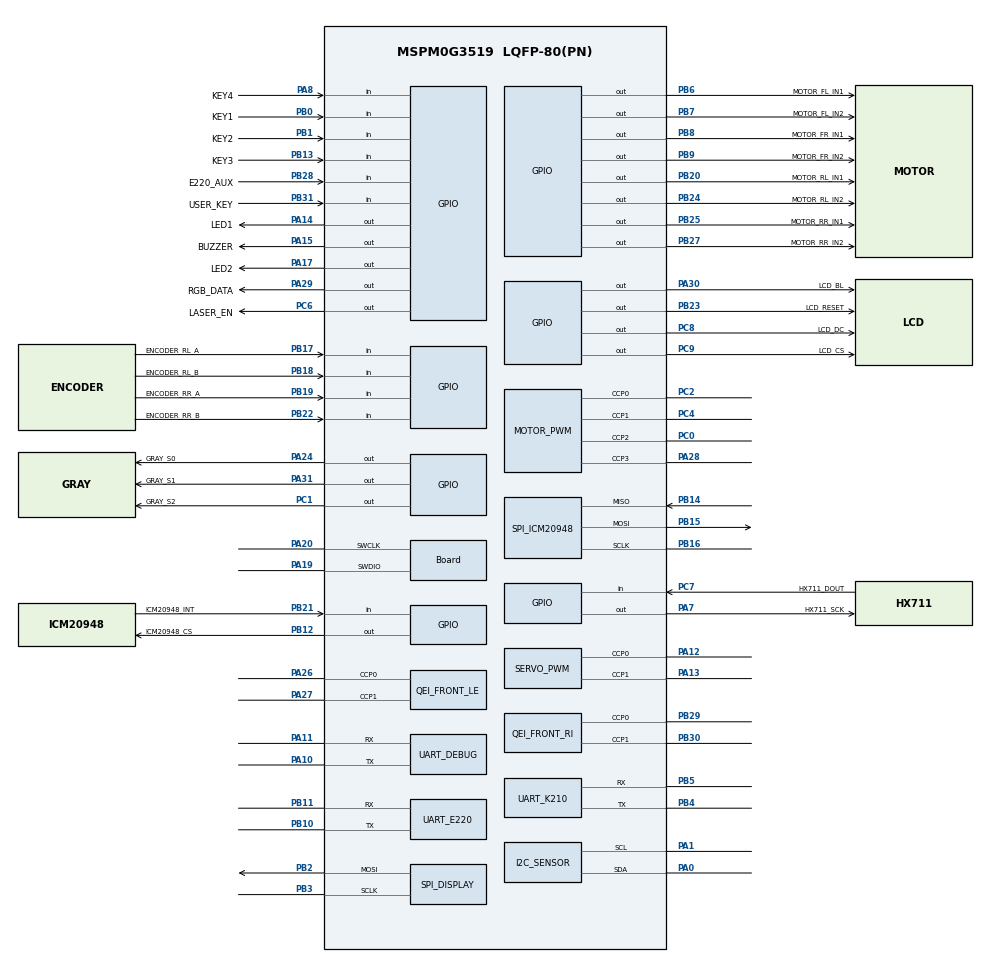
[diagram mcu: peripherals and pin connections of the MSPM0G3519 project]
//@cliArgs --device "MSPM0G351X" --package "LQFP-80(PN)" --part "Default"
//@v2CliArgs --device "MSPM0G3519" --package "LQFP-80(PN)"

/**
 * Import the modules used in this configuration.
 */
const Board         = scripting.addModule("/ti/driverlib/Board", {}, false);
const GPIO          = scripting.addModule("/ti/driverlib/GPIO", {}, false);
const GPIOA_BOARD   = GPIO.addInstance();
const GPIOB_BOARD   = GPIO.addInstance();
const GPIOC_BOARD   = GPIO.addInstance();
const PWM           = scripting.addModule("/ti/driverlib/PWM", {}, false);
const MOTOR_PWM     = PWM.addInstance();
const SERVO_PWM     = PWM.addInstance();
const QEI           = scripting.addModule("/ti/driverlib/QEI", {}, false);
const QEI_FRONT_LEFT  = QEI.addInstance();
const QEI_FRONT_RIGHT = QEI.addInstance();
const UART          = scripting.addModule("/ti/driverlib/UART", {}, false);
const UART_K210     = UART.addInstance();
const UART_E220     = UART.addInstance();
const UART_DEBUG    = UART.addInstance();
const I2C           = scripting.addModule("/ti/driverlib/I2C", {}, false);
const I2C_SENSOR    = I2C.addInstance();
const SPI           = scripting.addModule("/ti/driverlib/SPI", {}, false);
const SPI_DISPLAY   = SPI.addInstance();
const SPI_ICM20948  = SPI.addInstance();
const ADC12         = scripting.addModule("/ti/driverlib/ADC12", {}, false);
const ADC_GRAY      = ADC12.addInstance();
const SYSCTL        = scripting.addModule("/ti/driverlib/SYSCTL");
const SYSTICK       = scripting.addModule("/ti/driverlib/SYSTICK");
const ProjectConfig = scripting.addModule("/ti/project_config/ProjectConfig");

/**
 * Write custom configuration values to the imported modules.
 */

Board.peripheral.$assign          = "DEBUGSS";
Board.peripheral.swclkPin.$assign = "PA20";
Board.peripheral.swdioPin.$assign = "PA19";

GPIOA_BOARD.$name = "GPIO_BOARD_OUTPUTS";
GPIOA_BOARD.port  = "PORTA";
GPIOA_BOARD.associatedPins.create(9);

GPIOA_BOARD.associatedPins[0].$name        = "LED1";
GPIOA_BOARD.associatedPins[0].assignedPin  = "14";
GPIOA_BOARD.associatedPins[0].initialValue = "SET";
GPIOA_BOARD.associatedPins[0].pin.$assign  = "PA14";

GPIOA_BOARD.associatedPins[1].$name        = "LED2";
GPIOA_BOARD.associatedPins[1].assignedPin  = "17";
GPIOA_BOARD.associatedPins[1].initialValue = "SET";
GPIOA_BOARD.associatedPins[1].pin.$assign  = "PA17";

GPIOA_BOARD.associatedPins[2].$name        = "RGB_DATA";
GPIOA_BOARD.associatedPins[2].assignedPin  = "29";
GPIOA_BOARD.associatedPins[2].initialValue = "CLEARED";
GPIOA_BOARD.associatedPins[2].pin.$assign  = "PA29";

GPIOA_BOARD.associatedPins[3].$name        = "LCD_BL";
GPIOA_BOARD.associatedPins[3].assignedPin  = "30";
GPIOA_BOARD.associatedPins[3].initialValue = "CLEARED";
GPIOA_BOARD.associatedPins[3].pin.$assign  = "PA30";

GPIOA_BOARD.associatedPins[4].$name        = "GRAY_S0";
GPIOA_BOARD.associatedPins[4].assignedPin  = "24";
GPIOA_BOARD.associatedPins[4].initialValue = "CLEARED";
GPIOA_BOARD.associatedPins[4].pin.$assign  = "PA24";

GPIOA_BOARD.associatedPins[5].$name        = "GRAY_S1";
GPIOA_BOARD.associatedPins[5].assignedPin  = "31";
GPIOA_BOARD.associatedPins[5].initialValue = "CLEARED";
GPIOA_BOARD.associatedPins[5].pin.$assign  = "PA31";

GPIOA_BOARD.associatedPins[6].$name        = "HX711_SCK";
GPIOA_BOARD.associatedPins[6].assignedPin  = "7";
GPIOA_BOARD.associatedPins[6].initialValue = "CLEARED";
GPIOA_BOARD.associatedPins[6].pin.$assign  = "PA7";

GPIOA_BOARD.associatedPins[7].$name        = "BUZZER";
GPIOA_BOARD.associatedPins[7].assignedPin  = "15";
GPIOA_BOARD.associatedPins[7].initialValue = "SET";
GPIOA_BOARD.associatedPins[7].pin.$assign  = "PA15";
GPIOA_BOARD.associatedPins[8].$name            = "KEY4";
GPIOA_BOARD.associatedPins[8].assignedPin      = "8";
GPIOA_BOARD.associatedPins[8].direction        = "INPUT";
GPIOA_BOARD.associatedPins[8].internalResistor = "PULL_UP";
GPIOA_BOARD.associatedPins[8].pin.$assign      = "PA8";

GPIOB_BOARD.$name = "GPIO_BOARD_IO";
GPIOB_BOARD.port  = "PORTB";
GPIOB_BOARD.associatedPins.create(20);

GPIOB_BOARD.associatedPins[0].$name        = "ICM20948_CS";
GPIOB_BOARD.associatedPins[0].assignedPin  = "12";
GPIOB_BOARD.associatedPins[0].initialValue = "SET";
GPIOB_BOARD.associatedPins[0].pin.$assign  = "PB12";

GPIOB_BOARD.associatedPins[1].$name       = "ICM20948_INT";
GPIOB_BOARD.associatedPins[1].assignedPin = "21";
GPIOB_BOARD.associatedPins[1].direction   = "INPUT";
GPIOB_BOARD.associatedPins[1].interruptEn = true;
GPIOB_BOARD.associatedPins[1].polarity    = "RISE_FALL";
GPIOB_BOARD.associatedPins[1].pin.$assign = "PB21";

GPIOB_BOARD.associatedPins[2].$name            = "USER_KEY";
GPIOB_BOARD.associatedPins[2].assignedPin      = "31";
GPIOB_BOARD.associatedPins[2].direction        = "INPUT";
GPIOB_BOARD.associatedPins[2].internalResistor = "PULL_UP";
GPIOB_BOARD.associatedPins[2].pin.$assign      = "PB31";

GPIOB_BOARD.associatedPins[3].$name        = "MOTOR_FL_IN1";
GPIOB_BOARD.associatedPins[3].assignedPin  = "6";
GPIOB_BOARD.associatedPins[3].initialValue = "CLEARED";
GPIOB_BOARD.associatedPins[3].pin.$assign  = "PB6";

GPIOB_BOARD.associatedPins[4].$name        = "MOTOR_FL_IN2";
GPIOB_BOARD.associatedPins[4].assignedPin  = "7";
GPIOB_BOARD.associatedPins[4].initialValue = "CLEARED";
GPIOB_BOARD.associatedPins[4].pin.$assign  = "PB7";

GPIOB_BOARD.associatedPins[5].$name        = "MOTOR_FR_IN1";
GPIOB_BOARD.associatedPins[5].assignedPin  = "8";
GPIOB_BOARD.associatedPins[5].initialValue = "CLEARED";
GPIOB_BOARD.associatedPins[5].pin.$assign  = "PB8";

GPIOB_BOARD.associatedPins[6].$name        = "MOTOR_FR_IN2";
GPIOB_BOARD.associatedPins[6].assignedPin  = "9";
GPIOB_BOARD.associatedPins[6].initialValue = "CLEARED";
GPIOB_BOARD.associatedPins[6].pin.$assign  = "PB9";

GPIOB_BOARD.associatedPins[7].$name        = "MOTOR_RL_IN1";
GPIOB_BOARD.associatedPins[7].assignedPin  = "20";
GPIOB_BOARD.associatedPins[7].initialValue = "CLEARED";
GPIOB_BOARD.associatedPins[7].pin.$assign  = "PB20";

GPIOB_BOARD.associatedPins[8].$name        = "MOTOR_RL_IN2";
GPIOB_BOARD.associatedPins[8].assignedPin  = "24";
GPIOB_BOARD.associatedPins[8].initialValue = "CLEARED";
GPIOB_BOARD.associatedPins[8].pin.$assign  = "PB24";

GPIOB_BOARD.associatedPins[9].$name        = "MOTOR_RR_IN1";
GPIOB_BOARD.associatedPins[9].assignedPin  = "25";
GPIOB_BOARD.associatedPins[9].initialValue = "CLEARED";
GPIOB_BOARD.associatedPins[9].pin.$assign  = "PB25";

GPIOB_BOARD.associatedPins[10].$name        = "MOTOR_RR_IN2";
GPIOB_BOARD.associatedPins[10].assignedPin  = "27";
GPIOB_BOARD.associatedPins[10].initialValue = "CLEARED";
GPIOB_BOARD.associatedPins[10].pin.$assign  = "PB27";

GPIOB_BOARD.associatedPins[11].$name            = "ENCODER_RL_A";
GPIOB_BOARD.associatedPins[11].assignedPin      = "17";
GPIOB_BOARD.associatedPins[11].direction        = "INPUT";
GPIOB_BOARD.associatedPins[11].internalResistor = "PULL_UP";
GPIOB_BOARD.associatedPins[11].inputFilter      = "3_CYCLES";
GPIOB_BOARD.associatedPins[11].interruptEn      = true;
GPIOB_BOARD.associatedPins[11].polarity         = "RISE_FALL";
GPIOB_BOARD.associatedPins[11].pin.$assign      = "PB17";

GPIOB_BOARD.associatedPins[12].$name            = "ENCODER_RL_B";
GPIOB_BOARD.associatedPins[12].assignedPin      = "18";
GPIOB_BOARD.associatedPins[12].direction        = "INPUT";
GPIOB_BOARD.associatedPins[12].internalResistor = "PULL_UP";
GPIOB_BOARD.associatedPins[12].inputFilter      = "3_CYCLES";
GPIOB_BOARD.associatedPins[12].interruptEn      = true;
GPIOB_BOARD.associatedPins[12].polarity         = "RISE_FALL";
GPIOB_BOARD.associatedPins[12].pin.$assign      = "PB18";

GPIOB_BOARD.associatedPins[13].$name            = "ENCODER_RR_A";
GPIOB_BOARD.associatedPins[13].assignedPin      = "19";
GPIOB_BOARD.associatedPins[13].direction        = "INPUT";
GPIOB_BOARD.associatedPins[13].internalResistor = "PULL_UP";
GPIOB_BOARD.associatedPins[13].inputFilter      = "3_CYCLES";
GPIOB_BOARD.associatedPins[13].interruptEn      = true;
GPIOB_BOARD.associatedPins[13].polarity         = "RISE_FALL";
GPIOB_BOARD.associatedPins[13].pin.$assign      = "PB19";

GPIOB_BOARD.associatedPins[14].$name            = "ENCODER_RR_B";
GPIOB_BOARD.associatedPins[14].assignedPin      = "22";
GPIOB_BOARD.associatedPins[14].direction        = "INPUT";
GPIOB_BOARD.associatedPins[14].internalResistor = "PULL_UP";
GPIOB_BOARD.associatedPins[14].inputFilter      = "3_CYCLES";
GPIOB_BOARD.associatedPins[14].interruptEn      = true;
GPIOB_BOARD.associatedPins[14].polarity         = "RISE_FALL";
GPIOB_BOARD.associatedPins[14].pin.$assign      = "PB22";

GPIOB_BOARD.associatedPins[15].$name        = "LCD_RESET";
GPIOB_BOARD.associatedPins[15].assignedPin  = "23";
GPIOB_BOARD.associatedPins[15].initialValue = "SET";
GPIOB_BOARD.associatedPins[15].pin.$assign  = "PB23";

GPIOB_BOARD.associatedPins[16].$name            = "E220_AUX";
GPIOB_BOARD.associatedPins[16].assignedPin      = "28";
GPIOB_BOARD.associatedPins[16].direction        = "INPUT";
GPIOB_BOARD.associatedPins[16].internalResistor = "PULL_UP";
GPIOB_BOARD.associatedPins[16].pin.$assign      = "PB28";
GPIOB_BOARD.associatedPins[17].$name            = "KEY1";
GPIOB_BOARD.associatedPins[17].assignedPin      = "0";
GPIOB_BOARD.associatedPins[17].direction        = "INPUT";
GPIOB_BOARD.associatedPins[17].internalResistor = "PULL_UP";
GPIOB_BOARD.associatedPins[17].pin.$assign      = "PB0";

GPIOB_BOARD.associatedPins[18].$name            = "KEY2";
GPIOB_BOARD.associatedPins[18].assignedPin      = "1";
GPIOB_BOARD.associatedPins[18].direction        = "INPUT";
GPIOB_BOARD.associatedPins[18].internalResistor = "PULL_UP";
GPIOB_BOARD.associatedPins[18].pin.$assign      = "PB1";

GPIOB_BOARD.associatedPins[19].$name            = "KEY3";
GPIOB_BOARD.associatedPins[19].assignedPin      = "13";
GPIOB_BOARD.associatedPins[19].direction        = "INPUT";
GPIOB_BOARD.associatedPins[19].internalResistor = "PULL_UP";
GPIOB_BOARD.associatedPins[19].pin.$assign      = "PB13";

GPIOC_BOARD.$name = "GPIO_DISPLAY_GRAY";
GPIOC_BOARD.port  = "PORTC";
GPIOC_BOARD.associatedPins.create(5);

GPIOC_BOARD.associatedPins[0].$name        = "LCD_DC";
GPIOC_BOARD.associatedPins[0].assignedPin  = "8";
GPIOC_BOARD.associatedPins[0].initialValue = "CLEARED";
GPIOC_BOARD.associatedPins[0].pin.$assign  = "PC8";

GPIOC_BOARD.associatedPins[1].$name        = "LCD_CS";
GPIOC_BOARD.associatedPins[1].assignedPin  = "9";
GPIOC_BOARD.associatedPins[1].initialValue = "SET";
GPIOC_BOARD.associatedPins[1].pin.$assign  = "PC9";

GPIOC_BOARD.associatedPins[2].$name        = "GRAY_S2";
GPIOC_BOARD.associatedPins[2].assignedPin  = "1";
GPIOC_BOARD.associatedPins[2].initialValue = "CLEARED";
GPIOC_BOARD.associatedPins[2].pin.$assign  = "PC1";

GPIOC_BOARD.associatedPins[3].$name        = "LASER_EN";
GPIOC_BOARD.associatedPins[3].assignedPin  = "6";
GPIOC_BOARD.associatedPins[3].initialValue = "CLEARED";
GPIOC_BOARD.associatedPins[3].pin.$assign  = "PC6";

GPIOC_BOARD.associatedPins[4].$name            = "HX711_DOUT";
GPIOC_BOARD.associatedPins[4].assignedPin      = "7";
GPIOC_BOARD.associatedPins[4].direction        = "INPUT";
GPIOC_BOARD.associatedPins[4].internalResistor = "PULL_UP";
GPIOC_BOARD.associatedPins[4].pin.$assign      = "PC7";

/*
 * 四路直流电机 PWM 共用 TIMA0，32 MHz / 1600 = 20 kHz。
 * 所有通道初始占空比为 0，避免上电时电机误动作。
 */
MOTOR_PWM.$name                      = "PWM_MOTOR";
MOTOR_PWM.pwmMode                    = "EDGE_ALIGN_UP";
MOTOR_PWM.timerCount                 = 1600;
MOTOR_PWM.timerStartTimer            = true;
MOTOR_PWM.ccIndex                    = [0,1,2,3];
MOTOR_PWM.peripheral.$assign         = "TIMA0";
MOTOR_PWM.peripheral.ccp0Pin.$assign = "PC2";
MOTOR_PWM.peripheral.ccp1Pin.$assign = "PC4";
MOTOR_PWM.peripheral.ccp2Pin.$assign = "PC0";
MOTOR_PWM.peripheral.ccp3Pin.$assign = "PA28";
MOTOR_PWM.PWM_CHANNEL_0.$name        = "MOTOR_PWM_FL";
MOTOR_PWM.PWM_CHANNEL_0.ccValue      = 1600;
MOTOR_PWM.PWM_CHANNEL_1.$name        = "MOTOR_PWM_FR";
MOTOR_PWM.PWM_CHANNEL_1.ccValue      = 1600;
MOTOR_PWM.PWM_CHANNEL_2.$name        = "MOTOR_PWM_RL";
MOTOR_PWM.PWM_CHANNEL_2.ccValue      = 1600;
MOTOR_PWM.PWM_CHANNEL_3.$name        = "MOTOR_PWM_RR";
MOTOR_PWM.PWM_CHANNEL_3.ccValue      = 1600;

/*
 * TIMG0 以 1 MHz 计数、20 ms 周期驱动两路舵机。
 * 初始 compare=LOAD 表示 0% 有效脉冲，避免上电瞬间舵机误动作。
 */
SERVO_PWM.$name                      = "PWM_SERVO";
SERVO_PWM.pwmMode                    = "EDGE_ALIGN_UP";
SERVO_PWM.clockPrescale              = 32;
SERVO_PWM.timerCount                 = 20000;
SERVO_PWM.timerStartTimer            = true;
SERVO_PWM.ccIndex                    = [0,1];
SERVO_PWM.peripheral.$assign         = "TIMG0";
SERVO_PWM.peripheral.ccp0Pin.$assign = "PA12";
SERVO_PWM.peripheral.ccp1Pin.$assign = "PA13";
SERVO_PWM.PWM_CHANNEL_0.$name        = "SERVO_HORIZONTAL";
SERVO_PWM.PWM_CHANNEL_0.ccValue      = 20000;
SERVO_PWM.PWM_CHANNEL_1.$name        = "SERVO_PITCH";
SERVO_PWM.PWM_CHANNEL_1.ccValue      = 20000;

/*
 * MSPM0G3519 只有 TIMG8/TIMG9 两组硬件 QEI。
 * 先将它们固定给左右前轮；4WD 后轮后续使用 GPIO 双边沿软件解码。
 */
QEI_FRONT_LEFT.$name                      = "QEI_FRONT_LEFT";
QEI_FRONT_LEFT.timerStartTimer            = true;
QEI_FRONT_LEFT.peripheral.$assign         = "TIMG8";
QEI_FRONT_LEFT.peripheral.ccp0Pin.$assign = "PA26";
QEI_FRONT_LEFT.peripheral.ccp1Pin.$assign = "PA27";

QEI_FRONT_RIGHT.$name                      = "QEI_FRONT_RIGHT";
QEI_FRONT_RIGHT.timerStartTimer            = true;
QEI_FRONT_RIGHT.peripheral.$assign         = "TIMG9";
QEI_FRONT_RIGHT.peripheral.ccp0Pin.$assign = "PB29";
QEI_FRONT_RIGHT.peripheral.ccp1Pin.$assign = "PB30";

/*
 * 三路 UART 独立分工，均为 115200-8-N-1：
 * UART0：板载 CH340 / Type-C 调试串口，PA10 TX、PA11 RX；
 * UART1：K210，PB4 TX、PB5 RX；
 * UART4：E220，PB10 TX、PB11 RX。
 */
UART_DEBUG.$name                    = "UART_DEBUG";
UART_DEBUG.targetBaudRate           = 115200;
UART_DEBUG.enableFIFO               = true;
UART_DEBUG.rxFifoThreshold          = "DL_UART_RX_FIFO_LEVEL_ONE_ENTRY";
UART_DEBUG.txFifoThreshold          = "DL_UART_TX_FIFO_LEVEL_3_4_EMPTY";
UART_DEBUG.enabledInterrupts        = ["RX","TX"];
UART_DEBUG.peripheral.$assign       = "UART0";
UART_DEBUG.peripheral.txPin.$assign = "PA10";
UART_DEBUG.peripheral.rxPin.$assign = "PA11";

UART_K210.$name                    = "UART_K210";
UART_K210.targetBaudRate           = 115200;
UART_K210.enableFIFO               = true;
UART_K210.rxFifoThreshold          = "DL_UART_RX_FIFO_LEVEL_ONE_ENTRY";
UART_K210.txFifoThreshold          = "DL_UART_TX_FIFO_LEVEL_3_4_EMPTY";
UART_K210.enabledInterrupts        = ["RX","TX"];
UART_K210.peripheral.$assign       = "UART1";
UART_K210.peripheral.txPin.$assign = "PB4";
UART_K210.peripheral.rxPin.$assign = "PB5";

UART_E220.$name                    = "UART_E220";
UART_E220.targetBaudRate           = 115200;
UART_E220.enableFIFO               = true;
UART_E220.rxFifoThreshold          = "DL_UART_RX_FIFO_LEVEL_ONE_ENTRY";
UART_E220.txFifoThreshold          = "DL_UART_TX_FIFO_LEVEL_3_4_EMPTY";
UART_E220.enabledInterrupts        = ["RX","TX"];
UART_E220.peripheral.$assign       = "UART4";
UART_E220.peripheral.txPin.$assign = "PB10";
UART_E220.peripheral.rxPin.$assign = "PB11";

/* 传感器公共 I2C：OLED、VL53L1X、可选灰度 MCU 共用 400 kHz 总线。 */
I2C_SENSOR.$name                           = "I2C_SENSOR";
I2C_SENSOR.basicEnableController           = true;
I2C_SENSOR.basicControllerStandardBusSpeed = "Fast";
I2C_SENSOR.advAnalogGlitchFilter           = "DISABLED";
I2C_SENSOR.peripheral.$assign              = "I2C0";
I2C_SENSOR.peripheral.sdaPin.$assign       = "PA0";
I2C_SENSOR.peripheral.sclPin.$assign       = "PA1";
I2C_SENSOR.sdaPinConfig.enableConfig       = true;
I2C_SENSOR.sclPinConfig.enableConfig       = true;
I2C_SENSOR.DMAEvent1                       = "CONTROLLER_TXFIFO_TRIGGER";
I2C_SENSOR.DMAEvent2                       = "CONTROLLER_RXFIFO_TRIGGER";
I2C_SENSOR.intController                   = ["ARBITRATION_LOST","NACK","RX_DONE","TX_DONE"];
I2C_SENSOR.DMA_CHANNEL_EVENT1.$name        = "DMA_CH2";
I2C_SENSOR.DMA_CHANNEL_EVENT1.addressMode  = "b2f";
I2C_SENSOR.DMA_CHANNEL_EVENT1.srcLength    = "BYTE";
I2C_SENSOR.DMA_CHANNEL_EVENT1.dstLength    = "BYTE";
I2C_SENSOR.DMA_CHANNEL_EVENT1.peripheral.$assign = "DMA_CH2";
I2C_SENSOR.DMA_CHANNEL_EVENT2.$name        = "DMA_CH3";
I2C_SENSOR.DMA_CHANNEL_EVENT2.addressMode  = "f2b";
I2C_SENSOR.DMA_CHANNEL_EVENT2.srcLength    = "BYTE";
I2C_SENSOR.DMA_CHANNEL_EVENT2.dstLength    = "BYTE";
I2C_SENSOR.DMA_CHANNEL_EVENT2.peripheral.$assign = "DMA_CH3";

/*
 * 外接 ICM20948 使用 SPI1；显示屏使用 SPI0。
 * 两个 CS 都由 GPIO 软件控制，便于复用现有设备驱动事务边界。
 */
SPI_ICM20948.$name                      = "SPI_ICM20948";
SPI_ICM20948.targetBitRate              = 4000000;
SPI_ICM20948.rxFifoThreshold            = "DL_SPI_RX_FIFO_LEVEL_ONE_FRAME";
SPI_ICM20948.txFifoThreshold            = "DL_SPI_TX_FIFO_LEVEL_ONE_FRAME";
SPI_ICM20948.peripheral.$assign         = "SPI1";
SPI_ICM20948.peripheral.sclkPin.$assign = "PB16";
SPI_ICM20948.peripheral.mosiPin.$assign = "PB15";
SPI_ICM20948.peripheral.misoPin.$assign = "PB14";

SPI_DISPLAY.$name                      = "SPI_DISPLAY";
/* TFT 只发送，不需要 POCI/MISO；释放 PA10 给 UART0_TX。 */
SPI_DISPLAY.direction                  = "PICO";
SPI_DISPLAY.targetBitRate              = 8000000;
SPI_DISPLAY.rxFifoThreshold            = "DL_SPI_RX_FIFO_LEVEL_ONE_FRAME";
SPI_DISPLAY.txFifoThreshold            = "DL_SPI_TX_FIFO_LEVEL_ONE_FRAME";
SPI_DISPLAY.enabledDMAEvent1Triggers   = "DL_SPI_DMA_INTERRUPT_RX";
SPI_DISPLAY.enabledDMAEvent2Triggers   = "DL_SPI_DMA_INTERRUPT_TX";
SPI_DISPLAY.enabledInterrupts          = ["DMA_DONE_RX","DMA_DONE_TX","TX_EMPTY"];
SPI_DISPLAY.DMA_CHANNEL_EVENT1.$name   = "DMA_CH1";
SPI_DISPLAY.DMA_CHANNEL_EVENT1.addressMode = "f2b";
SPI_DISPLAY.DMA_CHANNEL_EVENT1.srcLength   = "BYTE";
SPI_DISPLAY.DMA_CHANNEL_EVENT1.dstLength   = "BYTE";
SPI_DISPLAY.DMA_CHANNEL_EVENT1.peripheral.$assign = "DMA_CH1";
SPI_DISPLAY.DMA_CHANNEL_EVENT2.$name   = "DMA_CH0";
SPI_DISPLAY.DMA_CHANNEL_EVENT2.addressMode = "b2f";
SPI_DISPLAY.DMA_CHANNEL_EVENT2.srcLength   = "BYTE";
SPI_DISPLAY.DMA_CHANNEL_EVENT2.dstLength   = "BYTE";
SPI_DISPLAY.DMA_CHANNEL_EVENT2.peripheral.$assign = "DMA_CH0";
SPI_DISPLAY.peripheral.$assign         = "SPI0";
SPI_DISPLAY.peripheral.sclkPin.$assign = "PB3";
SPI_DISPLAY.peripheral.mosiPin.$assign = "PB2";

/* 74HC4051 的模拟输出只占一路 ADC；S0/S1/S2 由 GPIO 切换。 */
ADC_GRAY.$name                       = "ADC_GRAY";
ADC_GRAY.sampClkSrc                  = "DL_ADC12_CLOCK_SYSOSC";
ADC_GRAY.sampClkDiv                  = "DL_ADC12_CLOCK_DIVIDE_8";
ADC_GRAY.sampleTime0                 = "125 us";
ADC_GRAY.adcMem0chansel              = "DL_ADC12_INPUT_CHAN_2";
ADC_GRAY.powerDownMode               = "DL_ADC12_POWER_DOWN_MODE_MANUAL";
ADC_GRAY.peripheral.$assign          = "ADC0";
ADC_GRAY.peripheral.adcPin2.$assign  = "PA25";

SYSCTL.forceDefaultClkConfig = true;
SYSCTL.clockTreeEn           = true;

/* 32 MHz 默认系统时钟下，32000 个周期产生 1 ms 系统节拍。 */
SYSTICK.period          = 32000;
SYSTICK.periodEnable    = true;
SYSTICK.systickEnable   = true;
SYSTICK.interruptEnable = true;

ProjectConfig.deviceSpin = "MSPM0G3519";
